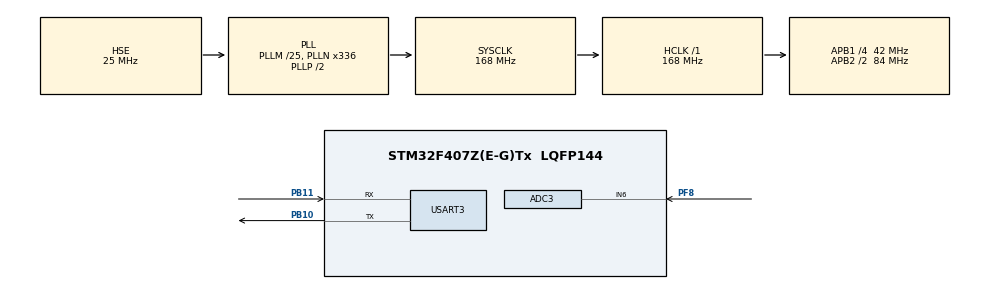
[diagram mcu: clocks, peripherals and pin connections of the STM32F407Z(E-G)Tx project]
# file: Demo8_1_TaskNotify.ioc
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ADC3.Channel-0\#ChannelRegularConversion=ADC_CHANNEL_6
ADC3.ExternalTrigConv=ADC_EXTERNALTRIGCONV_T3_TRGO
ADC3.NbrOfConversionFlag=1
ADC3.Rank-0\#ChannelRegularConversion=1
ADC3.SamplingTime-0\#ChannelRegularConversion=ADC_SAMPLETIME_15CYCLES
FREERTOS.Tasks01=Task_Show,24,256,AppTask_Show,Default,NULL,Dynamic,NULL,NULL
FREERTOS.configUSE_NEWLIB_REENTRANT=1
Mcu.Family=STM32F4
Mcu.Name=STM32F407Z(E-G)Tx
Mcu.Package=LQFP144
NVIC.ADC_IRQn=true\:5\:0\:false\:false\:true\:true\:true\:true\:true
NVIC.PriorityGroup=NVIC_PRIORITYGROUP_4
NVIC.TIM6_DAC_IRQn=true\:0\:0\:true\:false\:true\:false\:false\:true\:true
NVIC.TimeBase=TIM6_DAC_IRQn
NVIC.TimeBaseIP=TIM6
PA13.Mode=Serial_Wire
PA13.Signal=SYS_JTMS-SWDIO
PA14.Mode=Serial_Wire
PA14.Signal=SYS_JTCK-SWCLK
PB10.Mode=Asynchronous
PB10.Signal=USART3_TX
PB11.Mode=Asynchronous
PB11.Signal=USART3_RX
PF8.Mode=IN6
PF8.Signal=ADC3_IN6
PH0-OSC_IN.Mode=HSE-External-Oscillator
PH0-OSC_IN.Signal=RCC_OSC_IN
PH1-OSC_OUT.Mode=HSE-External-Oscillator
PH1-OSC_OUT.Signal=RCC_OSC_OUT
ProjectManager.HeapSize=0x200
ProjectManager.StackSize=0x400
ProjectManager.TargetToolchain=STM32CubeIDE
RCC.48MHZClocksFreq_Value=84000000
RCC.AHBFreq_Value=168000000
RCC.APB1CLKDivider=RCC_HCLK_DIV4
RCC.APB1Freq_Value=42000000
RCC.APB1TimFreq_Value=84000000
RCC.APB2CLKDivider=RCC_HCLK_DIV2
RCC.APB2Freq_Value=84000000
RCC.APB2TimFreq_Value=168000000
RCC.CortexFreq_Value=168000000
RCC.HCLKFreq_Value=168000000
RCC.HSE_VALUE=25000000
RCC.HSI_VALUE=16000000
RCC.LSE_VALUE=32768
RCC.PLLM=25
RCC.PLLN=336
RCC.PLLSourceVirtual=RCC_PLLSOURCE_HSE
RCC.SYSCLKFreq_VALUE=168000000
RCC.SYSCLKSource=RCC_SYSCLKSOURCE_PLLCLK
RCC.VCOOutputFreq_Value=336000000
TIM3.Period=499
TIM3.Prescaler=49999
TIM3.TIM_MasterOutputTrigger=TIM_TRGO_UPDATE
USART3.VirtualMode=VM_ASYNC
VP_FREERTOS_VS_CMSIS_V2.Mode=CMSIS_V2
VP_SYS_VS_tim6.Mode=TIM6
VP_TIM3_VS_ClockSourceINT.Mode=Internal
board=custom

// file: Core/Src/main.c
/* USER CODE BEGIN Header */
/**
  ******************************************************************************
  * @file           : main.c
  * @brief          : Main program body
  ******************************************************************************
  * @attention
  *
  * Copyright (c) 2025 STMicroelectronics.
  * All rights reserved.
  *
  * This software is licensed under terms that can be found in the LICENSE file
  * in the root directory of this software component.
  * If no LICENSE file comes with this software, it is provided AS-IS.
  *
  ******************************************************************************
  */
/* USER CODE END Header */
#include "main.h"
#include "cmsis_os.h"
#include "adc.h"
#include "tim.h"
#include "usart.h"
#include "gpio.h"

void SystemClock_Config(void);
void MX_FREERTOS_Init(void);

int main(void)
{

  /* MCU Configuration--------------------------------------------------------*/

  /* Reset of all peripherals, Initializes the Flash interface and the Systick. */
  HAL_Init();

  /* Configure the system clock */
  SystemClock_Config();

  /* Initialize all configured peripherals */
  MX_GPIO_Init();
  MX_USART3_UART_Init();
  MX_ADC3_Init();
  MX_TIM3_Init();
  /* USER CODE BEGIN 2 */
  // Start Menu
  uint8_t startstr[] = "Demo8_1:Task Notification.\r\n";
  HAL_UART_Transmit(&huart3,startstr,sizeof(startstr),0xFFFF);

  uint8_t startstr1[] = "Transfer ADC value by Notification.\r\n";
  HAL_UART_Transmit(&huart3,startstr1,sizeof(startstr1),0xFFFF);

  HAL_ADC_Start_IT(&hadc3);		//���жϷ�ʽ����ADC
  HAL_TIM_Base_Start(&htim3);		//����Timer
  /* USER CODE END 2 */

  /* Init scheduler */
  osKernelInitialize();

  /* Call init function for freertos objects (in cmsis_os2.c) */
  MX_FREERTOS_Init();

  /* Start scheduler */
  osKernelStart();

  /* We should never get here as control is now taken by the scheduler */

  /* Infinite loop */
  while (1)
  {

  }
}

void SystemClock_Config(void)
{
  RCC_OscInitTypeDef RCC_OscInitStruct = {0};
  RCC_ClkInitTypeDef RCC_ClkInitStruct = {0};

  /** Configure the main internal regulator output voltage
  */
  __HAL_RCC_PWR_CLK_ENABLE();
  __HAL_PWR_VOLTAGESCALING_CONFIG(PWR_REGULATOR_VOLTAGE_SCALE1);

  /** Initializes the RCC Oscillators according to the specified parameters
  * in the RCC_OscInitTypeDef structure.
  */
  RCC_OscInitStruct.OscillatorType = RCC_OSCILLATORTYPE_HSE;
  RCC_OscInitStruct.HSEState = RCC_HSE_ON;
  RCC_OscInitStruct.PLL.PLLState = RCC_PLL_ON;
  RCC_OscInitStruct.PLL.PLLSource = RCC_PLLSOURCE_HSE;
  RCC_OscInitStruct.PLL.PLLM = 25;
  RCC_OscInitStruct.PLL.PLLN = 336;
  RCC_OscInitStruct.PLL.PLLP = RCC_PLLP_DIV2;
  RCC_OscInitStruct.PLL.PLLQ = 4;
  if (HAL_RCC_OscConfig(&RCC_OscInitStruct) != HAL_OK)
  {
    Error_Handler();
  }

  /** Initializes the CPU, AHB and APB buses clocks
  */
  RCC_ClkInitStruct.ClockType = RCC_CLOCKTYPE_HCLK|RCC_CLOCKTYPE_SYSCLK
                              |RCC_CLOCKTYPE_PCLK1|RCC_CLOCKTYPE_PCLK2;
  RCC_ClkInitStruct.SYSCLKSource = RCC_SYSCLKSOURCE_PLLCLK;
  RCC_ClkInitStruct.AHBCLKDivider = RCC_SYSCLK_DIV1;
  RCC_ClkInitStruct.APB1CLKDivider = RCC_HCLK_DIV4;
  RCC_ClkInitStruct.APB2CLKDivider = RCC_HCLK_DIV2;

  if (HAL_RCC_ClockConfig(&RCC_ClkInitStruct, FLASH_LATENCY_5) != HAL_OK)
  {
    Error_Handler();
  }
}

void HAL_TIM_PeriodElapsedCallback(TIM_HandleTypeDef *htim)
{
  if (htim->Instance == TIM6)
  {
    HAL_IncTick();
  }
}

void Error_Handler(void)
{
  __disable_irq();
  while (1)
  {
  }
}

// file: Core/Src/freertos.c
/* USER CODE BEGIN Header */
/**
  ******************************************************************************
  * File Name          : freertos.c
  * Description        : Code for freertos applications
  ******************************************************************************
  * @attention
  *
  * Copyright (c) 2025 STMicroelectronics.
  * All rights reserved.
  *
  * This software is licensed under terms that can be found in the LICENSE file
  * in the root directory of this software component.
  * If no LICENSE file comes with this software, it is provided AS-IS.
  *
  ******************************************************************************
  */
/* USER CODE END Header */

#include "FreeRTOS.h"
#include "task.h"
#include "main.h"
#include "cmsis_os.h"

/* USER CODE BEGIN Includes */
#include <stdio.h>
#include "usart.h"
#include "adc.h"
/* USER CODE END Includes */

/* Definitions for Task_Show */
osThreadId_t Task_ShowHandle;
const osThreadAttr_t Task_Show_attributes = {
  .name = "Task_Show",
  .stack_size = 256 * 4,
  .priority = (osPriority_t) osPriorityNormal,
};

void AppTask_Show(void *argument);

void MX_FREERTOS_Init(void); /* (MISRA C 2004 rule 8.1) */

void MX_FREERTOS_Init(void) {

  /* Create the thread(s) */
  /* creation of Task_Show */
  Task_ShowHandle = osThreadNew(AppTask_Show, NULL, &Task_Show_attributes);

}

void AppTask_Show(void *argument)
{
	/* USER CODE BEGIN AppTask_Show */
	/* Infinite loop */
	uint32_t  notifyValue = 0;
	for(;;)
	{
		uint32_t ulBitsToClearOnEntry=0x00;				//进入时不清除数据
		uint32_t ulBitsToClearOnExit=0xFFFFFFFF;	//退出时清零数据
		BaseType_t result=xTaskNotifyWait(ulBitsToClearOnEntry, ulBitsToClearOnExit,
					&notifyValue, portMAX_DELAY);		//接收任务通知
		if (result==pdTRUE)
		{
			uint32_t tmpValue = notifyValue;				//ADC原始数值
		  	printf("Notify Value = %ld\r\n",tmpValue );

			uint32_t Volt = 3300*tmpValue;				//单位：mV
			Volt = Volt>>12;										//除以2^12
		  	printf("Engineering Value = %ld\r\n",Volt );
		}
	}
	/* USER CODE END AppTask_Show */
}

/* USER CODE BEGIN Application */
void HAL_ADC_ConvCpltCallback(ADC_HandleTypeDef* hadc)
{
	if (hadc->Instance != ADC3)
		return;

	uint32_t adc_value=HAL_ADC_GetValue(hadc);  	//Get ADC Value
	if (Task_ShowHandle != NULL)
	{
		BaseType_t taskWoken=pdFALSE;
		xTaskNotifyFromISR(Task_ShowHandle, adc_value,
				eSetValueWithOverwrite, &taskWoken);	//Transmit ADC
		portYIELD_FROM_ISR(taskWoken);  					//Required, context switch.
	}
}

int __io_putchar(int ch)
{
	HAL_UART_Transmit(&huart3,(uint8_t*)&ch,1,0xFFFF);
	return ch;
}
/* USER CODE END Application */
